# MCXN947_cm33_core0 register map
Vendor: nxp.com; File version: 1.0
CPU: CM33 r2p0, little endian, MPU, FPU, VTOR, 3 interrupt priority bits
Registers are 32-bit, read-write, reset 0x0 unless marked. A register's access mark holds for its fields unless they carry their own. Offsets are from the block's base; [hi:lo] are bit positions; {n}, {i} and the like mark numbered series; 'fields as' and 'values as' point back to an identical list.

## LPUART0 — LPUART
Base 0x40092000; alternate view of LPSPI0
Same registers: LPUART1 0x40093000 (alternate view of LPSPI1), LPUART2 0x40094000 (alternate view of LPSPI2), LPUART3 0x40095000 (alternate view of LPSPI3), LPUART4 0x400B4000 (alternate view of LPSPI4), LPUART5 0x400B5000 (alternate view of LPSPI5), LPUART6 0x400B6000 (alternate view of LPSPI6), LPUART7 0x400B7000 (alternate view of LPSPI7), LPUART8 0x400B8000 (alternate view of LPSPI8), LPUART9 0x400B9000 (alternate view of LPSPI9)
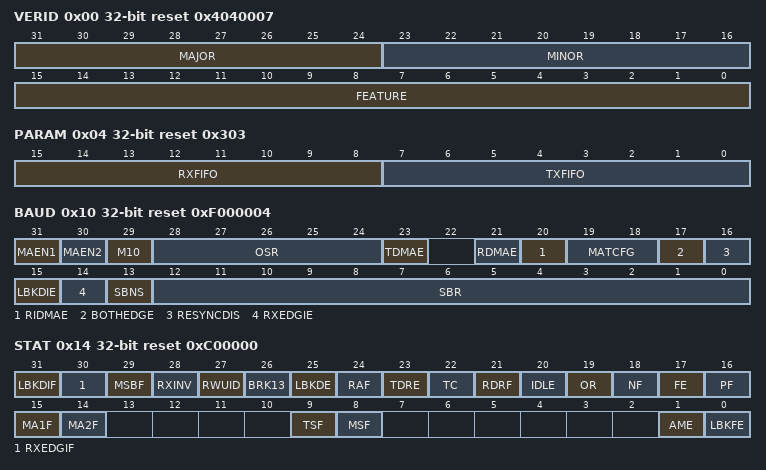
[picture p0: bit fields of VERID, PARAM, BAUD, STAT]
0x00 VERID ro reset 0x4040007 — Version ID
  [31:24] MAJOR — Major Version Number
  [23:16] MINOR — Minor Version Number
  [15:0] FEATURE — Feature Identification Number
    1=STANDARD (Standard feature set); 3=MODEM (Standard feature set with MODEM and IrDA support); 7=MODEM_IDLE (Enhanced feature set with full MODEM, IrDA, and enhanced idle detection)
0x04 PARAM ro reset 0x303 — Parameter
  [15:8] RXFIFO — Receive FIFO Size
  [7:0] TXFIFO — Transmit FIFO Size
0x08 GLOBAL
  [1] RST — Software Reset
    0=NO_EFFECT (Not reset); 1=RESET
0x0C PINCFG — Pin Configuration
  [1:0] TRGSEL — Trigger Select
    0=DISABLED (Input trigger disabled); 1=TRG_RXD (Input trigger used instead of the RXD pin input); 2=TRG_CTS (Input trigger used instead of the CTS_B pin input); 3=TRG_TXD (Input trigger used to modulate the TXD pin output, which (after TXINV configuration) is internally ANDed with the input trigger)
0x10 BAUD reset 0xF000004 — Baud Rate
  [31] MAEN1 — Match Address Mode Enable 1
    0=DISABLED (Disables); 1=ENABLED (Enables)
  [30] MAEN2 — Match Address Mode Enable 2
    0=DISABLED (Disables); 1=ENABLED (Enables)
  [29] M10 — 10-Bit Mode Select
    0=DISABLED (Receiver and transmitter use 7-bit to 9-bit data characters); 1=ENABLED (Receiver and transmitter use 10-bit data characters)
  [28:24] OSR — Oversampling Ratio (OSR)
    0=DEFAULT (Results in an OSR of 16); {v}=Results in an OSR of {v+1} (requires BAUD[BOTHEDGE] to be 1) (v=3..6); {v}=Results in an OSR of {v+1} (v=7..31)
  [23] TDMAE — Transmitter DMA Enable
    0=DISABLED (Disables DMA request); 1=ENABLED (Enables DMA request)
  [21] RDMAE — Receiver Full DMA Enable
    values as TDMAE
  [20] RIDMAE — Receiver Idle DMA Enable
    0=DISABLED (DMA request disabled); 1=ENABLED (DMA request enabled)
  [19:18] MATCFG — Match Configuration
    0=ADDR_MATCH (Address match wakeup); 1=IDLE_MATCH (Idle match wakeup); 2=ONOFF_MATCH (Match on and match off); 3=RWU_MATCH (Enables RWU on data match and match on/off for the transmitter CTS input)
  [17] BOTHEDGE — Both Edge Sampling
    0=DISABLED (Receiver samples input data using the rising edge of the baud rate clock); 1=ENABLED (Receiver samples input data using the rising and falling edges of the baud rate clock)
  [16] RESYNCDIS — Resynchronization Disable
    0=RESYNC (Enables resynchronization); 1=NO_RESYNC (Disables resynchronization)
  [15] LBKDIE — LIN Break Detect Interrupt Enable
    0=DISABLE (Disables hardware interrupts from STAT[LBKDIF] (uses polling)); 1=ENABLE (Requests hardware interrupt when STAT[LBKDIF] is 1)
  [14] RXEDGIE — RX Input Active Edge Interrupt Enable
    0=DISABLE (Disables hardware interrupts from STAT[RXEDGIF]); 1=ENABLE (Requests hardware interrupts when STAT[RXEDGIF] is 1)
  [13] SBNS — Stop Bit Number Select
    0=ONE (One stop bit); 1=TWO (Two stop bits)
  [12:0] SBR — Baud Rate Modulo Divisor
0x14 STAT reset 0xC00000 — Status
  [31] LBKDIF write-1-clears — LIN Break Detect Interrupt Flag
    0=NOT_DETECTED; 1=DETECTED
  [30] RXEDGIF write-1-clears — RXD Pin Active Edge Interrupt Flag
    0=NO_EDGE (Not occurred); 1=EDGE (Occurred)
  [29] MSBF — MSB First
    0=LSB_FIRST; 1=MSB_FIRST
  [28] RXINV — Receive Data Inversion
    0=NOT_INVERTED (Inverted); 1=INVERTED (Not inverted)
  [27] RWUID — Receive Wake Up Idle Detect
    0=IDLE_NOTSET (STAT[IDLE] does not become 1); 1=IDLE_SET (STAT[IDLE] becomes 1)
  [26] BRK13 — Break Character Generation Length
    0=SHORT (9 to 13 bit times); 1=LONG (12 to 15 bit times)
  [25] LBKDE — LIN Break Detection Enable
    0=DISABLED (Disables); 1=ENABLED (Enables)
  [24] RAF ro — Receiver Active Flag
    0=IDLE (Idle, waiting for a start bit); 1=ACTIVE (Receiver active (RXD pin input not idle))
  [23] TDRE ro — Transmit Data Register Empty Flag
    0=TXDATA (Greater than watermark); 1=NO_TXDATA (Equal to or less than watermark)
  [22] TC ro — Transmission Complete Flag
    0=ACTIVE (Transmitter active (sending data, a preamble, or a break)); 1=COMPLETE (Transmitter idle (transmission activity complete))
  [21] RDRF ro — Receive Data Register Full Flag
    0=NO_RXDATA (Equal to or less than watermark); 1=RXDATA (Greater than watermark)
  [20] IDLE write-1-clears — Idle Line Flag
    0=NOIDLE (No idle line detected); 1=IDLE (Idle line detected)
  [19] OR write-1-clears — Receiver Overrun Flag
    0=NO_OVERRUN; 1=OVERRUN (Receive overrun (new LPUART data lost))
  [18] NF write-1-clears — Noise Flag (NF)
    0=NONOISE (No noise detected); 1=NOISE (Noise detected)
  [17] FE write-1-clears — Framing Error Flag (FE)
    0=NOERROR (No framing error detected (this does not guarantee that the framing is correct)); 1=ERROR (Framing error detected)
  [16] PF write-1-clears — Parity Error Flag (PF)
    0=NOPARITY (No parity error detected); 1=PARITY (Parity error detected)
  [15] MA1F write-1-clears — Match 1 Flag
    0=NOMATCH (Not equal to MA1); 1=MATCH (Equal to MA1)
  [14] MA2F write-1-clears — Match 2 Flag
    0=NOMATCH (Not equal to MA2); 1=MATCH (Equal to MA2)
  [9] TSF ro — Timeout Status Flag
    0=NOFLAG (Field is 0); 1=FLAG (Field is 1)
  [8] MSF ro — MODEM Status Flag
    0=NOFLAG (Field is 0); 1=FLAG (Field is 1)
  [1] AME — Address Mark Enable
    0=DISABLED (Address mark in character is MSB); 1=ENABLED (Address mark in character is the last bit before the stop bit (or parity bit when enabled))
  [0] LBKFE — LIN Break Flag Enable
    0=DISABLED (Disables LIN break detect); 1=ENABLED (Enables LIN break detect)
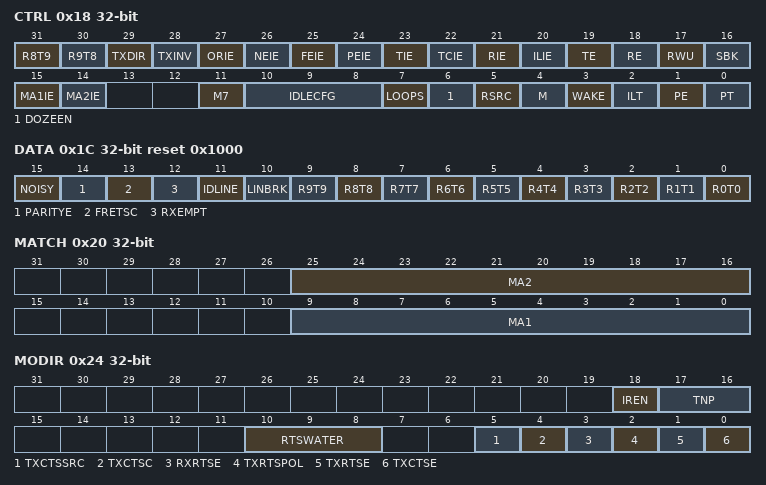
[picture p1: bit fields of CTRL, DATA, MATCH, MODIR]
0x18 CTRL — Control
  [31] R8T9 — Receive Bit 8 Transmit Bit 9
  [30] R9T8 — Receive Bit 9 Transmit Bit 8
  [29] TXDIR — TXD Pin Direction in Single-Wire Mode
    0=TX_INPUT (TXD pin is an input in Single-Wire mode); 1=TX_OUTPUT (TXD pin is an output in Single-Wire mode)
  [28] TXINV — Transmit Data Inversion
    0=NOT_INVERTED; 1=INVERTED
  [27] ORIE — Overrun Interrupt Enable
    0=DISABLED (Disables); 1=ENABLED (Enables)
  [26] NEIE — Noise Error Interrupt Enable
    0=DISABLED (Disables); 1=ENABLED (Enables)
  [25] FEIE — Framing Error Interrupt Enable
    0=DISABLED (Disables); 1=ENABLED (Enables)
  [24] PEIE — Parity Error Interrupt Enable
    0=DISABLED (Disables); 1=ENABLED (Enables)
  [23] TIE — Transmit Interrupt Enable
    0=DISABLED (Disables); 1=ENABLED (Enables)
  [22] TCIE — Transmission Complete Interrupt Enable
    0=DISABLED (Disables); 1=ENABLED (Enables)
  [21] RIE — Receiver Interrupt Enable
    0=DISABLED (Disables); 1=ENABLED (Enables)
  [20] ILIE — Idle Line Interrupt Enable
    0=DISABLED (Disables hardware interrupts from STAT[IDLE]; use polling); 1=ENABLED (Enables hardware interrupts when STAT[IDLE] = 1)
  [19] TE — Transmitter Enable
    0=DISABLED (Disables); 1=ENABLED (Enables)
  [18] RE — Receiver Enable
    0=DISABLED (Disables); 1=ENABLED (Enables)
  [17] RWU — Receiver Wakeup Control
    0=NO_EFFECT (Normal receiver operation); 1=RX_WAKEUP (LPUART receiver in standby, waiting for a wakeup condition)
  [16] SBK — Send Break
    0=NO_EFFECT (Normal transmitter operation); 1=TX_BREAK (Queue break character(s) to be sent)
  [15] MA1IE — Match 1 (MA1F) Interrupt Enable
    0=DISABLED (Disables); 1=ENABLED (Enables)
  [14] MA2IE — Match 2 (MA2F) Interrupt Enable
    0=DISABLED (Disables); 1=ENABLED (Enables)
  [11] M7 — 7-Bit Mode Select
    0=NO_EFFECT (8-bit to 10-bit data characters); 1=DATA7 (7-bit data characters)
  [10:8] IDLECFG — Idle Configuration
    0=IDLE_1 (1); 1=IDLE_2 (2); 2=IDLE_4 (4); 3=IDLE_8 (8); 4=IDLE_16 (16); 5=IDLE_32 (32); 6=IDLE_64 (64); 7=IDLE_128 (128)
  [7] LOOPS — Loop Mode Select
    0=NOFFECT (Normal operation: RXD and TXD use separate pins); 1=LOOPBACK (Loop mode or Single-Wire mode)
  [6] DOZEEN — Enables LPUART in Doze mode.
    0=ENABLED (Enables); 1=DISABLED (Disables)
  [5] RSRC — Receiver Source Select
    0=NO_EFFECT (Internal Loopback mode); 1=ONEWIRE (Single-wire mode)
  [4] M — 9-Bit Or 8-Bit Mode Select
    0=DATA8 (8-bit data characters); 1=DATA9 (9-bit data characters)
  [3] WAKE — Receiver Wakeup Method Select
    0=IDLE (Configures CTRL[RWU] for idle-line wakeup); 1=MARK (Configures CTRL[RWU] with address-mark wakeup)
  [2] ILT — Idle Line Type Select
    0=FROM_START (After the start bit); 1=FROM_STOP (After the stop bit)
  [1] PE — Parity Enable
    0=DISABLED (Disables); 1=ENABLED (Enables)
  [0] PT — Parity Type
    0=EVEN (Even parity); 1=ODD (Odd parity)
0x1C DATA reset 0x1000
  [15] NOISY ro — Noisy Data Received
    0=NO_NOISE (Received without noise); 1=NOISE (Received with noise)
  [14] PARITYE ro — Parity Error
    0=NO_PARITY (Received without a parity error); 1=PARITY (Received with a parity error)
  [13] FRETSC — Frame Error Transmit Special Character
    0=NO_ERROR (Received without a frame error on reads or transmits a normal character on writes); 1=ERROR (Received with a frame error on reads or transmits an idle or break character on writes)
  [12] RXEMPT ro — Receive Buffer Empty
    0=NOT_EMPTY (Contains valid data); 1=EMPTY (Contains invalid data and is empty)
  [11] IDLINE ro — Idle Line
    0=NO_IDLE (Received was not idle); 1=IDLE (Receiver was idle)
  [10] LINBRK ro — LIN Break
    0=NO_BREAK (LIN break not detected or LIN break detect circuitry disabled); 1=BREAK (LIN break detected)
  [n] R{n}T{n} (n=0..9) — Read Receive FIFO Bit {n} Or Write Transmit FIFO Bit {n}
0x20 MATCH — Match Address
  [25:16] MA2 — Match Address 2
  [9:0] MA1 — Match Address 1
0x24 MODIR — MODEM IrDA
  [18] IREN — IR Enable
    0=DISABLED (Disables); 1=ENABLED (Enables)
  [17:16] TNP — Transmitter Narrow Pulse
    0=ONE_SAMPLE (1 / OSR); 1=TWO_SAMPLE (2 / OSR); 2=THREE_SAMPLE (3 / OSR); 3=FOUR_SAMPLE (4 / OSR)
  [10:8] RTSWATER — Receive RTS Configuration
  [5] TXCTSSRC — Transmit CTS Source
    0=CTS (The CTS_B pin); 1=MATCH (An internal connection to the receiver address match result)
  [4] TXCTSC — Transmit CTS Configuration
    0=START (Sampled at the start of each character); 1=IDLE (Sampled when the transmitter is idle)
  [3] RXRTSE — Receiver RTS Enable
    0=DISABLED (Disables); 1=ENABLED (Enables)
  [2] TXRTSPOL — Transmitter RTS Polarity
    0=LOW (Transmitter RTS is active low); 1=HIGH (Transmitter RTS is active high)
  [1] TXRTSE — Transmitter RTS Enable
    0=DISABLED (Disables); 1=ENABLED (Enables)
  [0] TXCTSE — Transmitter CTS Enable
    0=DISABLED (Disables); 1=ENABLED (Enables)
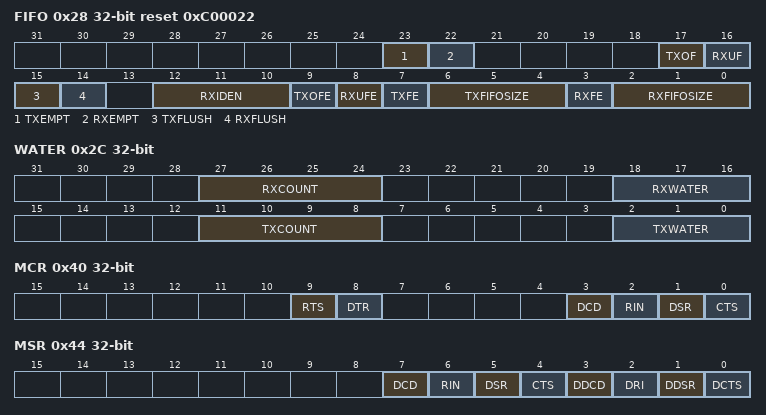
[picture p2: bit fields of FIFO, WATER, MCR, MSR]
0x28 FIFO reset 0xC00022
  [23] TXEMPT ro — Transmit FIFO Or Buffer Empty
    0=NOT_EMPTY; 1=EMPTY
  [22] RXEMPT ro — Receive FIFO Or Buffer Empty
    0=NOT_EMPTY; 1=EMPTY
  [17] TXOF write-1-clears — Transmitter FIFO Overflow Flag
    0=NO_OVERFLOW; 1=OVERFLOW
  [16] RXUF write-1-clears — Receiver FIFO Underflow Flag
    0=NO_UNDERFLOW; 1=UNDERFLOW
  [15] TXFLUSH — Transmit FIFO Flush
    0=NO_EFFECT; 1=TXFIFO_RST (All data is flushed out)
  [14] RXFLUSH — Receive FIFO Flush
    0=NO_EFFECT; 1=RXFIFO_RST (All data is flushed out)
  [12:10] RXIDEN — Receiver Idle Empty Enable
    0=DISABLED (Disables STAT[RDRF] to become 1 because of partially filled FIFO when the receiver is idle); 1=IDLE_1 (Enables STAT[RDRF] to become 1 because of partially filled FIFO when the receiver is idle for one character); 2=IDLE_2 (Enables STAT[RDRF] to become 1 because of partially filled FIFO when the receiver is idle for two characters); 3=IDLE_4 (Enables STAT[RDRF] to become 1 because of partially filled FIFO when the receiver is idle for four characters); 4=IDLE_8 (Enables STAT[RDRF] to become 1 because of partially filled FIFO when the receiver is idle for eight characters); 5=IDLE_16 (Enables STAT[RDRF] to become 1 because of partially filled FIFO when the receiver is idle for 16 characters); 6=IDLE_32 (Enables STAT[RDRF] to become 1 because of partially filled FIFO when the receiver is idle for 32 characters); 7=IDLE_64 (Enables STAT[RDRF] to become 1 because of partially filled FIFO when the receiver is idle for 64 characters)
  [9] TXOFE — Transmit FIFO Overflow Interrupt Enable
    0=DISABLED (Disables); 1=ENABLED (Enables)
  [8] RXUFE — Receive FIFO Underflow Interrupt Enable
    0=DISABLED (Disables); 1=ENABLED (Enables)
  [7] TXFE — Transmit FIFO Enable
    0=DISABLED (Disables; buffer depth is 1); 1=ENABLED (Enables; FIFO[TXFIFOSIZE] indicates the buffer depth)
  [6:4] TXFIFOSIZE ro — Transmit FIFO Buffer Depth
    0=FIFO_1 (Transmit FIFO buffer depth = 1 dataword); 1=FIFO_4 (Transmit FIFO buffer depth = 4 datawords); 2=FIFO_8 (Transmit FIFO buffer depth = 8 datawords); 3=FIFO_16 (Transmit FIFO buffer depth = 16 datawords); 4=FIFO_32 (Transmit FIFO buffer depth = 32 datawords); 5=FIFO_64 (Transmit FIFO buffer depth = 64 datawords); 6=FIFO_128 (Transmit FIFO buffer depth = 128 datawords); 7=FIFO_256 (Transmit FIFO buffer depth = 256 datawords)
  [3] RXFE — Receive FIFO Enable
    0=DISABLED (Disables; buffer depth is 1); 1=ENABLED (Enables; FIFO[RXFIFOSIZE] indicates the buffer depth)
  [2:0] RXFIFOSIZE ro — Receive FIFO Buffer Depth
    0=FIFO_1 (Receive FIFO buffer depth = 1 dataword); 1=FIFO_4 (Receive FIFO buffer depth = 4 datawords); 2=FIFO_8 (Receive FIFO buffer depth = 8 datawords); 3=FIFO_16 (Receive FIFO buffer depth = 16 datawords); 4=FIFO_32 (Receive FIFO buffer depth = 32 datawords); 5=FIFO_64 (Receive FIFO buffer depth = 64 datawords); 6=FIFO_128 (Receive FIFO buffer depth = 128 datawords); 7=FIFO_256 (Receive FIFO buffer depth = 256 datawords)
0x2C WATER — Watermark
  [27:24] RXCOUNT ro — Receive Counter
  [18:16] RXWATER — Receive Watermark
  [11:8] TXCOUNT ro — Transmit Counter
  [2:0] TXWATER — Transmit Watermark
0x30 DATARO ro reset 0x1000 — Data Read-Only
  [15:0] DATA — Receive Data
0x40 MCR — MODEM Control
  [9] RTS — Request To Send
    0=LOGIC_ONE (Default state is logic one); 1=LOGIC_ZERO (Default state is logic zero)
  [8] DTR — Data Terminal Ready
    values as RTS
  [3] DCD — Data Carrier Detect
    0=DISABLED (Interrupt disabled); 1=ENABLED (Interrupt enabled)
  [2] RIN — Ring Indicator
    values as DCD
  [1] DSR — Data Set Ready
    values as DCD
  [0] CTS — Clear To Send
    values as DCD
0x44 MSR — MODEM Status
  [7] DCD ro — Data Carrier Detect
    0=LOGIC_ONE (The DCD_B pin is logic one); 1=LOGIC_ZERO (The DCD_B pin is logic zero)
  [6] RIN ro — Ring Indicator
    0=LOGIC_ONE (The RIN_B pin is logic one); 1=LOGIC_ZERO (The RIN_B pin is logic zero)
  [5] DSR ro — Data Set Ready
    0=LOGIC_ONE (The DSR_B pin is logic one); 1=LOGIC_ZERO (The DSR_B pin is logic zero)
  [4] CTS ro — Clear To Send
    0=LOGIC_ONE (The CTS_B pin is logic one); 1=LOGIC_ZERO (The CTS_B pin is logic zero)
  [3] DDCD write-1-clears — Delta Data Carrier Detect
    0=NO_CHANGE (Did not change state); 1=CHANGE (Changed state)
  [2] DRI write-1-clears — Delta Ring Indicator
    0=NO_CHANGE (Did not change state); 1=CHANGE (Changed state)
  [1] DDSR write-1-clears — Delta Data Set Ready
    0=NO_CHANGE (Did not change state); 1=CHANGE (Changed state)
  [0] DCTS write-1-clears — Delta Clear To Send
    0=NO_CHANGE (Did not change state); 1=CHANGE (Changed state)
0x48 REIR — Receiver Extended Idle
  [13:0] IDTIME — Idle Time
0x4C TEIR — Transmitter Extended Idle
  [13:0] IDTIME — Idle Time
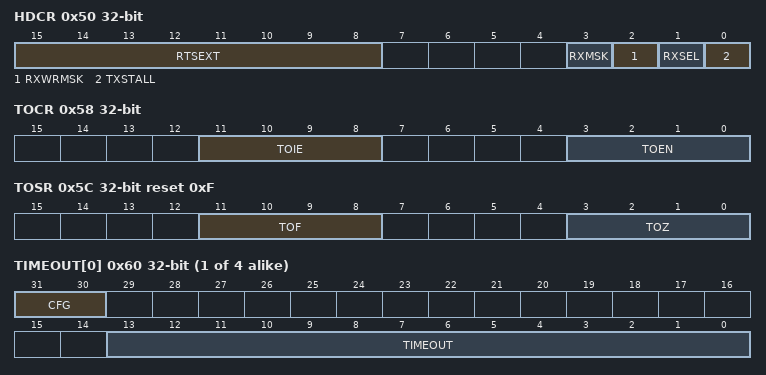
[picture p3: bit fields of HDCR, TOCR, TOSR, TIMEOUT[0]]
0x50 HDCR — Half Duplex Control
  [15:8] RTSEXT — RTS Extended
  [3] RXMSK — Receive Mask
    0=NO_EFFECT (Does not mask); 1=TX_RTS (Masks)
  [2] RXWRMSK — Receive FIFO Write Mask
    0=NO_EFFECT (Does not mask); 1=TX_RTS (Masks)
  [1] RXSEL — Receive Select
    0=PIN_RXD (RXD); 1=PIN_TXD (TXD)
  [0] TXSTALL — Transmit Stall
    0=NO_EFFECT; 1=RX_ACTIVE (Does not become busy)
0x58 TOCR — Timeout Control
  [11:8] TOIE — Timeout Interrupt Enable
  [3:0] TOEN — Timeout Enable
0x5C TOSR reset 0xF — Timeout Status
  [11:8] TOF write-1-clears — Timeout Flag
  [3:0] TOZ ro — Timeout Zero
{0x60+4i} TIMEOUT[{i}] (i=0..3) — Timeout N
  [31:30] CFG — Idle Configuration
    0=CNT_CHAR (Becomes 1 after timeout characters are received); 1=CNT_IDLE (Becomes 1 when idle for timeout bit clocks); 2=CNT_BUSY_IDLE (Becomes 1 when idle for timeout bit clocks following the next character); 3=CNT_CHAR_IDLE (Becomes 1 when idle for at least timeout bit clocks, but a new character is detected before the extended idle timeout is reached)
  [13:0] TIMEOUT — Timeout Value
{0x200+4i} TCBR[{i}] (i=0..127) wo — Transmit Command Burst
  [15:0] DATA
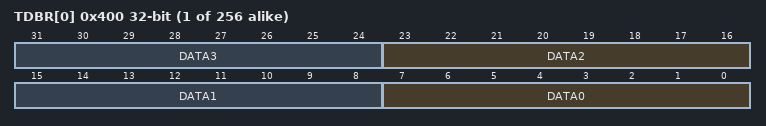
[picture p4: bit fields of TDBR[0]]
{0x400+4i} TDBR[{i}] (i=0..255) wo — Transmit Data Burst
  [8n+7:8n] DATA{n} (n=0..3)
